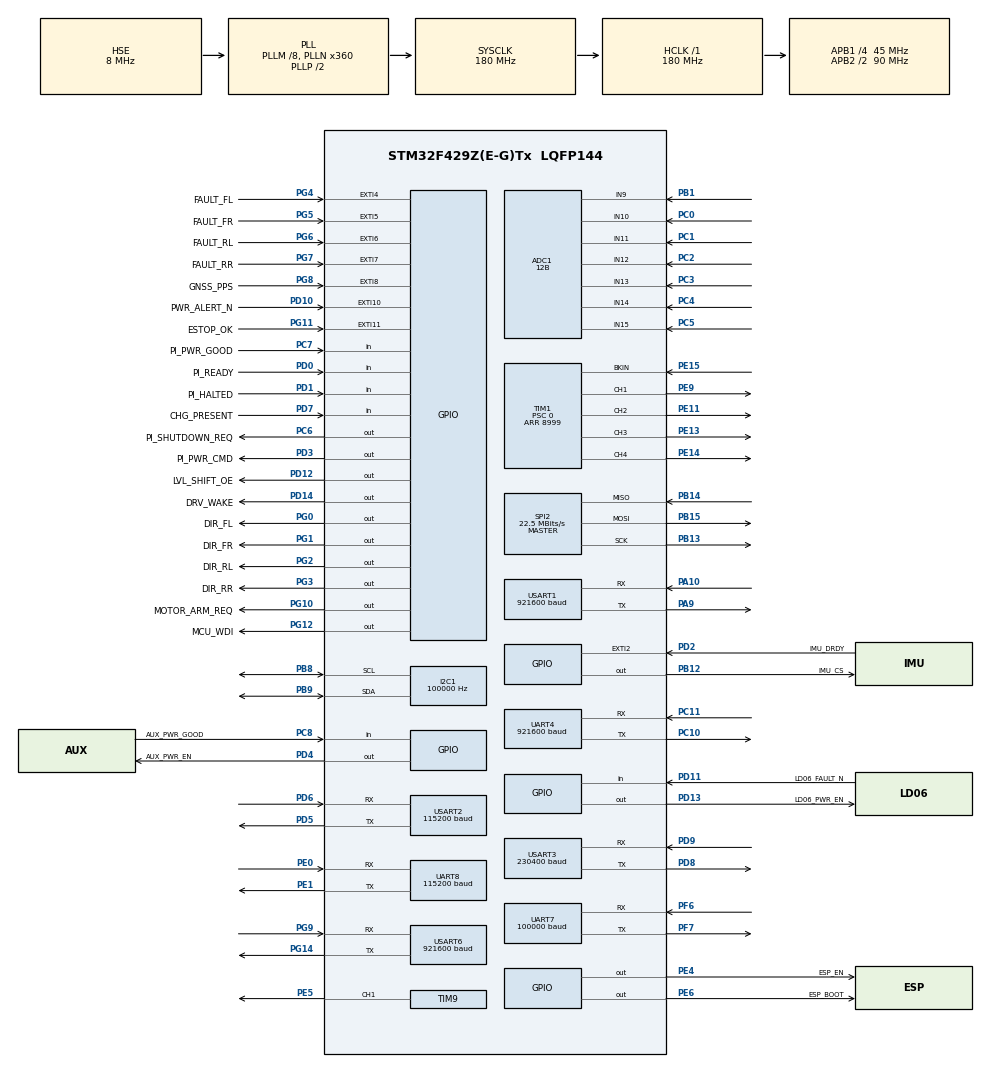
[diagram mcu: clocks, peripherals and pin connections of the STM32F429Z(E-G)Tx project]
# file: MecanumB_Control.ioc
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ADC1.Channel-0\#ChannelRegularConversion=ADC_CHANNEL_10
ADC1.Channel-1\#ChannelRegularConversion=ADC_CHANNEL_11
ADC1.Channel-2\#ChannelRegularConversion=ADC_CHANNEL_12
ADC1.Channel-3\#ChannelRegularConversion=ADC_CHANNEL_13
ADC1.Channel-4\#ChannelRegularConversion=ADC_CHANNEL_14
ADC1.Channel-5\#ChannelRegularConversion=ADC_CHANNEL_15
ADC1.Channel-6\#ChannelRegularConversion=ADC_CHANNEL_9
ADC1.ClockPrescaler=ADC_CLOCK_SYNC_PCLK_DIV4
ADC1.ContinuousConvMode=DISABLE
ADC1.DMAContinuousRequests=ENABLE
ADC1.EOCSelection=ADC_EOC_SINGLE_CONV
ADC1.ExternalTrigConv=ADC_EXTERNALTRIGCONV_T8_TRGO
ADC1.ExternalTrigConvEdge=ADC_EXTERNALTRIGCONVEDGE_RISING
ADC1.NbrOfConversion=7
ADC1.NbrOfConversionFlag=1
ADC1.Rank-0\#ChannelRegularConversion=1
ADC1.Rank-1\#ChannelRegularConversion=2
ADC1.Rank-2\#ChannelRegularConversion=3
ADC1.Rank-3\#ChannelRegularConversion=4
ADC1.Rank-4\#ChannelRegularConversion=5
ADC1.Rank-5\#ChannelRegularConversion=6
ADC1.Rank-6\#ChannelRegularConversion=7
ADC1.Resolution=ADC_RESOLUTION_12B
ADC1.SamplingTime-0\#ChannelRegularConversion=ADC_SAMPLETIME_56CYCLES
ADC1.SamplingTime-1\#ChannelRegularConversion=ADC_SAMPLETIME_56CYCLES
ADC1.SamplingTime-2\#ChannelRegularConversion=ADC_SAMPLETIME_56CYCLES
ADC1.SamplingTime-3\#ChannelRegularConversion=ADC_SAMPLETIME_56CYCLES
ADC1.SamplingTime-4\#ChannelRegularConversion=ADC_SAMPLETIME_56CYCLES
ADC1.SamplingTime-5\#ChannelRegularConversion=ADC_SAMPLETIME_56CYCLES
ADC1.SamplingTime-6\#ChannelRegularConversion=ADC_SAMPLETIME_144CYCLES
ADC1.ScanConvMode=ENABLE
ADC1.master=1
Dma.ADC1.0.Direction=DMA_PERIPH_TO_MEMORY
Dma.ADC1.0.FIFOMode=DMA_FIFOMODE_DISABLE
Dma.ADC1.0.Instance=DMA2_Stream0
Dma.ADC1.0.MemDataAlignment=DMA_MDATAALIGN_HALFWORD
Dma.ADC1.0.MemInc=DMA_MINC_ENABLE
Dma.ADC1.0.Mode=DMA_CIRCULAR
Dma.ADC1.0.PeriphDataAlignment=DMA_PDATAALIGN_HALFWORD
Dma.ADC1.0.PeriphInc=DMA_PINC_DISABLE
Dma.ADC1.0.Priority=DMA_PRIORITY_HIGH
Dma.Request0=ADC1
Dma.Request1=UART7_RX
Dma.Request2=USART2_RX
Dma.Request3=USART3_RX
Dma.Request4=UART4_RX
Dma.Request5=USART6_RX
Dma.Request6=USART6_TX
Dma.Request7=USART1_RX
Dma.Request8=USART1_TX
Dma.UART4_RX.4.Direction=DMA_PERIPH_TO_MEMORY
Dma.UART4_RX.4.FIFOMode=DMA_FIFOMODE_DISABLE
Dma.UART4_RX.4.Instance=DMA1_Stream2
Dma.UART4_RX.4.MemDataAlignment=DMA_MDATAALIGN_BYTE
Dma.UART4_RX.4.MemInc=DMA_MINC_ENABLE
Dma.UART4_RX.4.Mode=DMA_CIRCULAR
Dma.UART4_RX.4.PeriphDataAlignment=DMA_PDATAALIGN_BYTE
Dma.UART4_RX.4.PeriphInc=DMA_PINC_DISABLE
Dma.UART4_RX.4.Priority=DMA_PRIORITY_HIGH
Dma.UART7_RX.1.Direction=DMA_PERIPH_TO_MEMORY
Dma.UART7_RX.1.FIFOMode=DMA_FIFOMODE_DISABLE
Dma.UART7_RX.1.Instance=DMA1_Stream3
Dma.UART7_RX.1.MemDataAlignment=DMA_MDATAALIGN_BYTE
Dma.UART7_RX.1.MemInc=DMA_MINC_ENABLE
Dma.UART7_RX.1.Mode=DMA_CIRCULAR
Dma.UART7_RX.1.PeriphDataAlignment=DMA_PDATAALIGN_BYTE
Dma.UART7_RX.1.PeriphInc=DMA_PINC_DISABLE
Dma.UART7_RX.1.Priority=DMA_PRIORITY_VERY_HIGH
Dma.USART1_RX.7.Direction=DMA_PERIPH_TO_MEMORY
Dma.USART1_RX.7.FIFOMode=DMA_FIFOMODE_DISABLE
Dma.USART1_RX.7.Instance=DMA2_Stream2
Dma.USART1_RX.7.MemDataAlignment=DMA_MDATAALIGN_BYTE
Dma.USART1_RX.7.MemInc=DMA_MINC_ENABLE
Dma.USART1_RX.7.Mode=DMA_CIRCULAR
Dma.USART1_RX.7.PeriphDataAlignment=DMA_PDATAALIGN_BYTE
Dma.USART1_RX.7.PeriphInc=DMA_PINC_DISABLE
Dma.USART1_RX.7.Priority=DMA_PRIORITY_HIGH
Dma.USART1_TX.8.Direction=DMA_MEMORY_TO_PERIPH
Dma.USART1_TX.8.FIFOMode=DMA_FIFOMODE_DISABLE
Dma.USART1_TX.8.Instance=DMA2_Stream7
Dma.USART1_TX.8.MemDataAlignment=DMA_MDATAALIGN_BYTE
Dma.USART1_TX.8.MemInc=DMA_MINC_ENABLE
Dma.USART1_TX.8.Mode=DMA_NORMAL
Dma.USART1_TX.8.PeriphDataAlignment=DMA_PDATAALIGN_BYTE
Dma.USART1_TX.8.PeriphInc=DMA_PINC_DISABLE
Dma.USART1_TX.8.Priority=DMA_PRIORITY_MEDIUM
Dma.USART2_RX.2.Direction=DMA_PERIPH_TO_MEMORY
Dma.USART2_RX.2.FIFOMode=DMA_FIFOMODE_DISABLE
Dma.USART2_RX.2.Instance=DMA1_Stream5
Dma.USART2_RX.2.MemDataAlignment=DMA_MDATAALIGN_BYTE
Dma.USART2_RX.2.MemInc=DMA_MINC_ENABLE
Dma.USART2_RX.2.Mode=DMA_CIRCULAR
Dma.USART2_RX.2.PeriphDataAlignment=DMA_PDATAALIGN_BYTE
Dma.USART2_RX.2.PeriphInc=DMA_PINC_DISABLE
Dma.USART2_RX.2.Priority=DMA_PRIORITY_HIGH
Dma.USART3_RX.3.Direction=DMA_PERIPH_TO_MEMORY
Dma.USART3_RX.3.FIFOMode=DMA_FIFOMODE_DISABLE
Dma.USART3_RX.3.Instance=DMA1_Stream1
Dma.USART3_RX.3.MemDataAlignment=DMA_MDATAALIGN_BYTE
Dma.USART3_RX.3.MemInc=DMA_MINC_ENABLE
Dma.USART3_RX.3.Mode=DMA_CIRCULAR
Dma.USART3_RX.3.PeriphDataAlignment=DMA_PDATAALIGN_BYTE
Dma.USART3_RX.3.PeriphInc=DMA_PINC_DISABLE
Dma.USART3_RX.3.Priority=DMA_PRIORITY_HIGH
Dma.USART6_RX.5.Direction=DMA_PERIPH_TO_MEMORY
Dma.USART6_RX.5.FIFOMode=DMA_FIFOMODE_DISABLE
Dma.USART6_RX.5.Instance=DMA2_Stream1
Dma.USART6_RX.5.MemDataAlignment=DMA_MDATAALIGN_BYTE
Dma.USART6_RX.5.MemInc=DMA_MINC_ENABLE
Dma.USART6_RX.5.Mode=DMA_CIRCULAR
Dma.USART6_RX.5.PeriphDataAlignment=DMA_PDATAALIGN_BYTE
Dma.USART6_RX.5.PeriphInc=DMA_PINC_DISABLE
Dma.USART6_RX.5.Priority=DMA_PRIORITY_HIGH
Dma.USART6_TX.6.Direction=DMA_MEMORY_TO_PERIPH
Dma.USART6_TX.6.FIFOMode=DMA_FIFOMODE_DISABLE
Dma.USART6_TX.6.Instance=DMA2_Stream6
Dma.USART6_TX.6.MemDataAlignment=DMA_MDATAALIGN_BYTE
Dma.USART6_TX.6.MemInc=DMA_MINC_ENABLE
Dma.USART6_TX.6.Mode=DMA_NORMAL
Dma.USART6_TX.6.PeriphDataAlignment=DMA_PDATAALIGN_BYTE
Dma.USART6_TX.6.PeriphInc=DMA_PINC_DISABLE
Dma.USART6_TX.6.Priority=DMA_PRIORITY_MEDIUM
FREERTOS.Tasks01=defaultTask,0,128,StartDefaultTask,Default,NULL,Dynamic,NULL,NULL
FREERTOS.configCHECK_FOR_STACK_OVERFLOW=2
FREERTOS.configLIBRARY_MAX_SYSCALL_INTERRUPT_PRIORITY=5
FREERTOS.configMAX_PRIORITIES=16
FREERTOS.configMINIMAL_STACK_SIZE=128
FREERTOS.configTICK_RATE_HZ=1000
FREERTOS.configTOTAL_HEAP_SIZE=32768
FREERTOS.configUSE_16_BIT_TICKS=0
FREERTOS.configUSE_COUNTING_SEMAPHORES=1
FREERTOS.configUSE_IDLE_HOOK=0
FREERTOS.configUSE_MALLOC_FAILED_HOOK=1
FREERTOS.configUSE_MUTEXES=1
FREERTOS.configUSE_PORT_OPTIMISED_TASK_SELECTION=1
FREERTOS.configUSE_PREEMPTION=1
FREERTOS.configUSE_STATS_FORMATTING_FUNCTIONS=1
FREERTOS.configUSE_TICK_HOOK=0
FREERTOS.configUSE_TIMERS=0
FREERTOS.configUSE_TRACE_FACILITY=1
I2C1.ClockSpeed=100000
IWDG.Prescaler=IWDG_PRESCALER_32
IWDG.Reload=500
Mcu.Family=STM32F4
Mcu.Name=STM32F429Z(E-G)Tx
Mcu.Package=LQFP144
NVIC.DMA1_Stream1_IRQn=true\:6\:0\:true\:false\:true\:true\:true\:true\:true
NVIC.DMA1_Stream2_IRQn=true\:6\:0\:true\:false\:true\:true\:true\:true\:true
NVIC.DMA1_Stream3_IRQn=true\:6\:0\:true\:false\:true\:true\:true\:true\:true
NVIC.DMA1_Stream5_IRQn=true\:6\:0\:true\:false\:true\:true\:true\:true\:true
NVIC.DMA2_Stream0_IRQn=true\:6\:0\:true\:false\:true\:true\:true\:true\:true
NVIC.DMA2_Stream1_IRQn=true\:6\:0\:true\:false\:true\:true\:true\:true\:true
NVIC.DMA2_Stream2_IRQn=true\:6\:0\:true\:false\:true\:true\:true\:true\:true
NVIC.DMA2_Stream6_IRQn=true\:6\:0\:true\:false\:true\:true\:true\:true\:true
NVIC.DMA2_Stream7_IRQn=true\:6\:0\:true\:false\:true\:true\:true\:true\:true
NVIC.EXTI15_10_IRQn=true\:5\:0\:false\:false\:true\:true\:true\:true\:true
NVIC.EXTI2_IRQn=true\:6\:0\:true\:false\:true\:true\:true\:true\:true
NVIC.EXTI4_IRQn=true\:5\:0\:false\:false\:true\:true\:true\:true\:true
NVIC.EXTI9_5_IRQn=true\:5\:0\:false\:false\:true\:true\:true\:true\:true
NVIC.PriorityGroup=NVIC_PRIORITYGROUP_4
NVIC.TIM1_BRK_TIM9_IRQn=true\:5\:0\:false\:false\:true\:true\:true\:true\:true
NVIC.TIM6_DAC_IRQn=true\:5\:0\:true\:false\:true\:true\:true\:true\:true
NVIC.TIM7_IRQn=true\:14\:0\:false\:false\:true\:false\:false\:true\:true
NVIC.TimeBase=TIM7_IRQn
NVIC.TimeBaseIP=TIM7
NVIC.UART4_IRQn=true\:7\:0\:true\:false\:true\:true\:true\:true\:true
NVIC.UART7_IRQn=true\:7\:0\:true\:false\:true\:true\:true\:true\:true
NVIC.USART1_IRQn=true\:7\:0\:true\:false\:true\:true\:true\:true\:true
NVIC.USART2_IRQn=true\:7\:0\:true\:false\:true\:true\:true\:true\:true
NVIC.USART3_IRQn=true\:7\:0\:true\:false\:true\:true\:true\:true\:true
NVIC.USART6_IRQn=true\:7\:0\:true\:false\:true\:true\:true\:true\:true
PA0/WKUP.Signal=S_TIM5_CH1
PA1.Signal=S_TIM5_CH2
PA10.Mode=Asynchronous
PA10.Signal=USART1_RX
PA13.Mode=Serial_Wire
PA13.Signal=SYS_JTMS-SWDIO
PA14.Mode=Serial_Wire
PA14.Signal=SYS_JTCK-SWCLK
PA15.Signal=S_TIM2_CH1_ETR
PA6.Signal=S_TIM3_CH1
PA7.Signal=S_TIM3_CH2
PA9.Mode=Asynchronous
PA9.Signal=USART1_TX
PB1.Signal=ADCx_IN9
PB12.GPIO_Label=IMU_CS
PB12.GPIO_PuPd=GPIO_PULLUP
PB12.PinState=GPIO_PIN_SET
PB12.Signal=GPIO_Output
PB13.Mode=Full_Duplex_Master
PB13.Signal=SPI2_SCK
PB14.Mode=Full_Duplex_Master
PB14.Signal=SPI2_MISO
PB15.Mode=Full_Duplex_Master
PB15.Signal=SPI2_MOSI
PB3.Signal=S_TIM2_CH2
PB6.Signal=S_TIM4_CH1
PB7.Signal=S_TIM4_CH2
PB8.Mode=I2C
PB8.Signal=I2C1_SCL
PB9.Mode=I2C
PB9.Signal=I2C1_SDA
PC0.Signal=ADCx_IN10
PC1.Signal=ADCx_IN11
PC10.Mode=Asynchronous
PC10.Signal=UART4_TX
PC11.Mode=Asynchronous
PC11.Signal=UART4_RX
PC2.Signal=ADCx_IN12
PC3.Signal=ADCx_IN13
PC4.Signal=ADCx_IN14
PC5.Signal=ADCx_IN15
PC6.GPIO_Label=PI_SHUTDOWN_REQ
PC6.PinState=GPIO_PIN_RESET
PC6.Signal=GPIO_Output
PC7.GPIO_Label=PI_PWR_GOOD
PC7.GPIO_PuPd=GPIO_NOPULL
PC7.Signal=GPIO_Input
PC8.GPIO_Label=AUX_PWR_GOOD
PC8.GPIO_PuPd=GPIO_NOPULL
PC8.Signal=GPIO_Input
PD0.GPIO_Label=PI_READY
PD0.GPIO_PuPd=GPIO_PULLDOWN
PD0.Signal=GPIO_Input
PD1.GPIO_Label=PI_HALTED
PD1.GPIO_PuPd=GPIO_PULLDOWN
PD1.Signal=GPIO_Input
PD10.GPIO_Label=PWR_ALERT_N
PD10.GPIO_ModeDefaultEXTI=GPIO_MODE_IT_FALLING
PD10.GPIO_PuPd=GPIO_PULLUP
PD10.Signal=GPXTI10
PD11.GPIO_Label=LD06_FAULT_N
PD11.GPIO_PuPd=GPIO_PULLUP
PD11.Signal=GPIO_Input
PD12.GPIO_Label=LVL_SHIFT_OE
PD12.GPIO_PuPd=GPIO_PULLDOWN
PD12.Signal=GPIO_Output
PD13.GPIO_Label=LD06_PWR_EN
PD13.PinState=GPIO_PIN_RESET
PD13.GPIO_PuPd=GPIO_NOPULL
PD13.Signal=GPIO_Output
PD14.GPIO_Label=DRV_WAKE
PD14.PinState=GPIO_PIN_RESET
PD14.Signal=GPIO_Output
PD2.GPIO_Label=IMU_DRDY
PD2.GPIO_ModeDefaultEXTI=GPIO_MODE_IT_RISING
PD2.GPIO_PuPd=GPIO_PULLDOWN
PD2.Signal=GPXTI2
PD3.GPIO_Label=PI_PWR_CMD
PD3.PinState=GPIO_PIN_RESET
PD3.Signal=GPIO_Output
PD4.GPIO_Label=AUX_PWR_EN
PD4.PinState=GPIO_PIN_RESET
PD4.Signal=GPIO_Output
PD5.Mode=Asynchronous
PD5.Signal=USART2_TX
PD6.Mode=Asynchronous
PD6.Signal=USART2_RX
PD7.GPIO_Label=CHG_PRESENT
PD7.GPIO_PuPd=GPIO_NOPULL
PD7.Signal=GPIO_Input
PD8.Mode=Asynchronous
PD8.Signal=USART3_TX
PD9.Mode=Asynchronous
PD9.Signal=USART3_RX
PE0.Mode=Asynchronous
PE0.Signal=UART8_RX
PE1.Mode=Asynchronous
PE1.Signal=UART8_TX
PE11.Signal=S_TIM1_CH2
PE13.Signal=S_TIM1_CH3
PE14.Signal=S_TIM1_CH4
PE15.Mode=Activate-Break-Input
PE15.Signal=TIM1_BKIN
PE5.Signal=S_TIM9_CH1
PE9.Signal=S_TIM1_CH1
PF6.Mode=Asynchronous
PF6.Signal=UART7_RX
PF7.Mode=Asynchronous
PF7.Signal=UART7_TX
PG0.GPIO_Label=DIR_FL
PG0.PinState=GPIO_PIN_RESET
PG0.Signal=GPIO_Output
PG1.GPIO_Label=DIR_FR
PG1.PinState=GPIO_PIN_RESET
PG1.Signal=GPIO_Output
PG10.GPIO_Label=MOTOR_ARM_REQ
PG10.GPIO_PuPd=GPIO_PULLDOWN
PG10.Signal=GPIO_Output
PG11.GPIO_Label=ESTOP_OK
PG11.GPIO_ModeDefaultEXTI=GPIO_MODE_IT_FALLING
PG11.GPIO_PuPd=GPIO_PULLUP
PG11.Signal=GPXTI11
PG12.GPIO_Label=MCU_WDI
PG12.PinState=GPIO_PIN_RESET
PG12.Signal=GPIO_Output
PG14.Mode=Asynchronous
PG14.Signal=USART6_TX
PG2.GPIO_Label=DIR_RL
PG2.PinState=GPIO_PIN_RESET
PG2.Signal=GPIO_Output
PG3.GPIO_Label=DIR_RR
PG3.PinState=GPIO_PIN_RESET
PG3.Signal=GPIO_Output
PG4.GPIO_Label=FAULT_FL
PG4.GPIO_ModeDefaultEXTI=GPIO_MODE_IT_FALLING
PG4.GPIO_PuPd=GPIO_PULLUP
PG4.Signal=GPXTI4
PG5.GPIO_Label=FAULT_FR
PG5.GPIO_ModeDefaultEXTI=GPIO_MODE_IT_FALLING
PG5.GPIO_PuPd=GPIO_PULLUP
PG5.Signal=GPXTI5
PG6.GPIO_Label=FAULT_RL
PG6.GPIO_ModeDefaultEXTI=GPIO_MODE_IT_FALLING
PG6.GPIO_PuPd=GPIO_PULLUP
PG6.Signal=GPXTI6
PG7.GPIO_Label=FAULT_RR
PG7.GPIO_ModeDefaultEXTI=GPIO_MODE_IT_FALLING
PG7.GPIO_PuPd=GPIO_PULLUP
PG7.Signal=GPXTI7
PG8.GPIO_Label=GNSS_PPS
PG8.GPIO_ModeDefaultEXTI=GPIO_MODE_IT_RISING
PG8.GPIO_PuPd=GPIO_PULLDOWN
PG8.Signal=GPXTI8
PG9.Mode=Asynchronous
PG9.Signal=USART6_RX
PH0/OSC_IN.Mode=HSE-External-Oscillator
PH0/OSC_IN.Signal=RCC_OSC_IN
PH1/OSC_OUT.Mode=HSE-External-Oscillator
PH1/OSC_OUT.Signal=RCC_OSC_OUT
ProjectManager.HeapSize=0x200
ProjectManager.StackSize=0x400
ProjectManager.TargetToolchain=STM32CubeIDE
RCC.48MHZClocksFreq_Value=45000000
RCC.AHBCLKDivider=RCC_SYSCLK_DIV1
RCC.AHBFreq_Value=180000000
RCC.APB1CLKDivider=RCC_HCLK_DIV4
RCC.APB1Freq_Value=45000000
RCC.APB1TimFreq_Value=90000000
RCC.APB2CLKDivider=RCC_HCLK_DIV2
RCC.APB2Freq_Value=90000000
RCC.APB2TimFreq_Value=180000000
RCC.CortexFreq_Value=180000000
RCC.HCLKFreq_Value=180000000
RCC.HSE_VALUE=8000000
RCC.HSI_VALUE=16000000
RCC.LSE_VALUE=32768
RCC.PLLM=8
RCC.PLLN=360
RCC.PLLQ=8
RCC.PLLSAIN=192
RCC.SYSCLKFreq_VALUE=180000000
RCC.SYSCLKSource=RCC_SYSCLKSOURCE_PLLCLK
RCC.VCOOutputFreq_Value=360000000
SH.ADCx_IN10.0=ADC1_IN10,IN10
SH.ADCx_IN11.0=ADC1_IN11,IN11
SH.ADCx_IN12.0=ADC1_IN12,IN12
SH.ADCx_IN13.0=ADC1_IN13,IN13
SH.ADCx_IN14.0=ADC1_IN14,IN14
SH.ADCx_IN15.0=ADC1_IN15,IN15
SH.ADCx_IN9.0=ADC1_IN9,IN9
SH.S_TIM1_CH1.0=TIM1_CH1,PWM Generation1 CH1
SH.S_TIM1_CH2.0=TIM1_CH2,PWM Generation2 CH2
SH.S_TIM1_CH3.0=TIM1_CH3,PWM Generation3 CH3
SH.S_TIM1_CH4.0=TIM1_CH4,PWM Generation4 CH4
SH.S_TIM2_CH1_ETR.0=TIM2_CH1
SH.S_TIM2_CH2.0=TIM2_CH2
SH.S_TIM3_CH1.0=TIM3_CH1
SH.S_TIM3_CH2.0=TIM3_CH2
SH.S_TIM4_CH1.0=TIM4_CH1
SH.S_TIM4_CH2.0=TIM4_CH2
SH.S_TIM5_CH1.0=TIM5_CH1
SH.S_TIM5_CH2.0=TIM5_CH2
SH.S_TIM9_CH1.0=TIM9_CH1,PWM Generation1 CH1
SPI2.BaudRatePrescaler=SPI_BAUDRATEPRESCALER_4
SPI2.CLKPhase=SPI_PHASE_1EDGE
SPI2.CLKPolarity=SPI_POLARITY_LOW
SPI2.CalculateBaudRate=22.5 MBits/s
SPI2.DataSize=SPI_DATASIZE_8BIT
SPI2.Direction=SPI_DIRECTION_2LINES
SPI2.FirstBit=SPI_FIRSTBIT_MSB
SPI2.Mode=SPI_MODE_MASTER
SPI2.NSS=SPI_NSS_SOFT
SPI2.VirtualType=VM_MASTER
TIM1.AutomaticOutput=TIM_AUTOMATICOUTPUT_DISABLE
TIM1.BreakPolarity=TIM_BREAKPOLARITY_HIGH
TIM1.BreakState=TIM_BREAK_ENABLE
TIM1.Channel-PWM\ Generation1\ CH1=TIM_CHANNEL_1
TIM1.Channel-PWM\ Generation2\ CH2=TIM_CHANNEL_2
TIM1.Channel-PWM\ Generation3\ CH3=TIM_CHANNEL_3
TIM1.Channel-PWM\ Generation4\ CH4=TIM_CHANNEL_4
TIM1.CounterMode=TIM_COUNTERMODE_UP
TIM1.Period=8999
TIM1.Prescaler=0
TIM2.CombinedChannels=Encoder Mode
TIM2.EncoderMode=TIM_ENCODERMODE_TI12
TIM2.IC1Filter=0
TIM2.IC1Polarity=TIM_ICPOLARITY_RISING
TIM2.IC1Prescaler=TIM_ICPSC_DIV1
TIM2.IC1Selection=TIM_ICSELECTION_DIRECTTI
TIM2.IC2Filter=0
TIM2.IC2Polarity=TIM_ICPOLARITY_RISING
TIM2.IC2Prescaler=TIM_ICPSC_DIV1
TIM2.IC2Selection=TIM_ICSELECTION_DIRECTTI
TIM2.Period=4294967295
TIM2.Prescaler=0
TIM3.CombinedChannels=Encoder Mode
TIM3.EncoderMode=TIM_ENCODERMODE_TI12
TIM3.IC1Filter=0
TIM3.IC1Polarity=TIM_ICPOLARITY_RISING
TIM3.IC1Prescaler=TIM_ICPSC_DIV1
TIM3.IC1Selection=TIM_ICSELECTION_DIRECTTI
TIM3.IC2Filter=0
TIM3.IC2Polarity=TIM_ICPOLARITY_RISING
TIM3.IC2Prescaler=TIM_ICPSC_DIV1
TIM3.IC2Selection=TIM_ICSELECTION_DIRECTTI
TIM3.Period=65535
TIM3.Prescaler=0
TIM4.CombinedChannels=Encoder Mode
TIM4.EncoderMode=TIM_ENCODERMODE_TI12
TIM4.IC1Filter=0
TIM4.IC1Polarity=TIM_ICPOLARITY_RISING
TIM4.IC1Prescaler=TIM_ICPSC_DIV1
TIM4.IC1Selection=TIM_ICSELECTION_DIRECTTI
TIM4.IC2Filter=0
TIM4.IC2Polarity=TIM_ICPOLARITY_RISING
TIM4.IC2Prescaler=TIM_ICPSC_DIV1
TIM4.IC2Selection=TIM_ICSELECTION_DIRECTTI
TIM4.Period=65535
TIM4.Prescaler=0
TIM5.CombinedChannels=Encoder Mode
TIM5.EncoderMode=TIM_ENCODERMODE_TI12
TIM5.IC1Filter=0
TIM5.IC1Polarity=TIM_ICPOLARITY_RISING
TIM5.IC1Prescaler=TIM_ICPSC_DIV1
TIM5.IC1Selection=TIM_ICSELECTION_DIRECTTI
TIM5.IC2Filter=0
TIM5.IC2Polarity=TIM_ICPOLARITY_RISING
TIM5.IC2Prescaler=TIM_ICPSC_DIV1
TIM5.IC2Selection=TIM_ICSELECTION_DIRECTTI
TIM5.Period=4294967295
TIM5.Prescaler=0
TIM6.Period=999
TIM6.Prescaler=89
TIM8.Period=8999
TIM8.Prescaler=0
TIM8.TIM_MasterOutputTrigger=TIM_TRGO_UPDATE
TIM9.Channel-PWM\ Generation1\ CH1=TIM_CHANNEL_1
TIM9.Period=5999
TIM9.Prescaler=0
UART4.BaudRate=921600
UART4.VirtualMode=Asynchronous
UART7.BaudRate=100000
UART7.Parity=PARITY_EVEN
UART7.StopBits=UART_STOPBITS_2
UART7.VirtualMode=Asynchronous
UART7.WordLength=WORDLENGTH_9B
UART8.BaudRate=115200
UART8.VirtualMode=Asynchronous
USART1.BaudRate=921600
USART1.VirtualMode=VM_ASYNC
USART2.BaudRate=115200
USART2.VirtualMode=VM_ASYNC
USART3.BaudRate=230400
USART3.VirtualMode=VM_ASYNC
USART6.BaudRate=921600
USART6.VirtualMode=VM_ASYNC
VP_FREERTOS_VS_CMSIS_V1.Mode=CMSIS_V1
VP_IWDG_VS_IWDG.Mode=IWDG_Activate
VP_SYS_VS_tim7.Mode=TIM7
VP_TIM1_VS_ClockSourceINT.Mode=Internal
VP_TIM2_VS_ClockSourceINT.Mode=Internal
VP_TIM3_VS_ClockSourceINT.Mode=Internal
VP_TIM4_VS_ClockSourceINT.Mode=Internal
VP_TIM5_VS_ClockSourceINT.Mode=Internal
VP_TIM6_VS_ClockSourceINT.Mode=Enable_Timer
VP_TIM8_VS_ClockSourceINT.Mode=Internal
VP_TIM9_VS_ClockSourceINT.Mode=Internal
board=custom
RCC.PLLSourceVirtual=RCC_PLLSOURCE_HSE
PE4.GPIO_Label=ESP_EN
PE4.GPIO_ModeDefaultOutputPP=GPIO_MODE_OUTPUT_OD
PE4.PinState=GPIO_PIN_SET
PE4.Signal=GPIO_Output
PE6.GPIO_Label=ESP_BOOT
PE6.GPIO_ModeDefaultOutputPP=GPIO_MODE_OUTPUT_OD
PE6.PinState=GPIO_PIN_SET
PE6.Signal=GPIO_Output

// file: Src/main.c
/* USER CODE BEGIN Header */
/**
  ******************************************************************************
  * @file           : main.c
  * @brief          : Main program body
  ******************************************************************************
  * @attention
  *
  * Copyright (c) 2026 STMicroelectronics.
  * All rights reserved.
  *
  * This software is licensed under terms that can be found in the LICENSE file
  * in the root directory of this software component.
  * If no LICENSE file comes with this software, it is provided AS-IS.
  *
  ******************************************************************************
  */
/* USER CODE END Header */
#include "main.h"
#include "FreeRTOS.h"
#include "task.h"
#include "vehicle_app.h"

ADC_HandleTypeDef hadc1;
DMA_HandleTypeDef hdma_adc1;

I2C_HandleTypeDef hi2c1;

IWDG_HandleTypeDef hiwdg;

SPI_HandleTypeDef hspi2;

TIM_HandleTypeDef htim1;
TIM_HandleTypeDef htim2;
TIM_HandleTypeDef htim3;
TIM_HandleTypeDef htim4;
TIM_HandleTypeDef htim5;
TIM_HandleTypeDef htim6;
TIM_HandleTypeDef htim8;
TIM_HandleTypeDef htim9;

UART_HandleTypeDef huart4;
UART_HandleTypeDef huart7;
UART_HandleTypeDef huart8;
UART_HandleTypeDef huart1;
UART_HandleTypeDef huart2;
UART_HandleTypeDef huart3;
UART_HandleTypeDef huart6;
DMA_HandleTypeDef hdma_uart4_rx;
DMA_HandleTypeDef hdma_uart7_rx;
DMA_HandleTypeDef hdma_usart1_rx;
DMA_HandleTypeDef hdma_usart1_tx;
DMA_HandleTypeDef hdma_usart2_rx;
DMA_HandleTypeDef hdma_usart3_rx;
DMA_HandleTypeDef hdma_usart6_rx;
DMA_HandleTypeDef hdma_usart6_tx;

void SystemClock_Config(void);
static void MX_GPIO_Init(void);
static void MX_DMA_Init(void);
static void MX_ADC1_Init(void);
static void MX_I2C1_Init(void);
static void MX_IWDG_Init(void);
static void MX_SPI2_Init(void);
static void MX_TIM1_Init(void);
static void MX_TIM2_Init(void);
static void MX_TIM3_Init(void);
static void MX_TIM4_Init(void);
static void MX_TIM5_Init(void);
static void MX_TIM6_Init(void);
static void MX_TIM8_Init(void);
static void MX_TIM9_Init(void);
static void MX_UART4_Init(void);
static void MX_UART7_Init(void);
static void MX_UART8_Init(void);
static void MX_USART1_UART_Init(void);
static void MX_USART2_UART_Init(void);
static void MX_USART3_UART_Init(void);
static void MX_USART6_UART_Init(void);

int main(void)
{

  /* MCU Configuration--------------------------------------------------------*/

  /* Reset of all peripherals, Initializes the Flash interface and the Systick. */
  HAL_Init();

  /* Configure the system clock */
  SystemClock_Config();

  /* Initialize all configured peripherals */
  MX_GPIO_Init();
  MX_DMA_Init();
  MX_ADC1_Init();
  MX_I2C1_Init();
  MX_SPI2_Init();
  MX_TIM1_Init();
  MX_TIM2_Init();
  MX_TIM3_Init();
  MX_TIM4_Init();
  MX_TIM5_Init();
  MX_TIM6_Init();
  MX_TIM8_Init();
  MX_TIM9_Init();
  MX_UART4_Init();
  MX_UART7_Init();
  MX_UART8_Init();
  MX_USART1_UART_Init();
  MX_USART2_UART_Init();
  MX_USART3_UART_Init();
  MX_USART6_UART_Init();

  /* Create the thread(s) */
  /* definition and creation of defaultTask */
  vehicle_app_init();
  /* Start the independent watchdog only after parameter-store boot recovery:
   * a full 128 KiB sector erase can exceed the 500 ms timeout. */
  MX_IWDG_Init();

  /* Start scheduler */
  vTaskStartScheduler();
  Error_Handler();

  /* We should never get here as control is now taken by the scheduler */

  /* Infinite loop */
  while (1)
  {

  }
}

void SystemClock_Config(void)
{
  RCC_OscInitTypeDef RCC_OscInitStruct = {0};
  RCC_ClkInitTypeDef RCC_ClkInitStruct = {0};

  /** Configure the main internal regulator output voltage
  */
  __HAL_RCC_PWR_CLK_ENABLE();
  __HAL_PWR_VOLTAGESCALING_CONFIG(PWR_REGULATOR_VOLTAGE_SCALE1);

  /** Initializes the RCC Oscillators according to the specified parameters
  * in the RCC_OscInitTypeDef structure.
  */
  RCC_OscInitStruct.OscillatorType = RCC_OSCILLATORTYPE_HSE|RCC_OSCILLATORTYPE_LSI;
  RCC_OscInitStruct.HSEState = RCC_HSE_ON;
  RCC_OscInitStruct.HSIState = RCC_HSI_ON;
  RCC_OscInitStruct.HSICalibrationValue = RCC_HSICALIBRATION_DEFAULT;
  RCC_OscInitStruct.LSIState = RCC_LSI_ON;
  RCC_OscInitStruct.PLL.PLLState = RCC_PLL_ON;
  RCC_OscInitStruct.PLL.PLLSource = RCC_PLLSOURCE_HSE;
  RCC_OscInitStruct.PLL.PLLM = 8;
  RCC_OscInitStruct.PLL.PLLN = 360;
  RCC_OscInitStruct.PLL.PLLP = RCC_PLLP_DIV2;
  RCC_OscInitStruct.PLL.PLLQ = 8;
  if (HAL_RCC_OscConfig(&RCC_OscInitStruct) != HAL_OK)
  {
    Error_Handler();
  }

  /** Activate the Over-Drive mode
  */
  if (HAL_PWREx_EnableOverDrive() != HAL_OK)
  {
    Error_Handler();
  }

  /** Initializes the CPU, AHB and APB buses clocks
  */
  RCC_ClkInitStruct.ClockType = RCC_CLOCKTYPE_HCLK|RCC_CLOCKTYPE_SYSCLK
                              |RCC_CLOCKTYPE_PCLK1|RCC_CLOCKTYPE_PCLK2;
  RCC_ClkInitStruct.SYSCLKSource = RCC_SYSCLKSOURCE_PLLCLK;
  RCC_ClkInitStruct.AHBCLKDivider = RCC_SYSCLK_DIV1;
  RCC_ClkInitStruct.APB1CLKDivider = RCC_HCLK_DIV4;
  RCC_ClkInitStruct.APB2CLKDivider = RCC_HCLK_DIV2;

  if (HAL_RCC_ClockConfig(&RCC_ClkInitStruct, FLASH_LATENCY_5) != HAL_OK)
  {
    Error_Handler();
  }
}

static void MX_ADC1_Init(void)
{

  ADC_ChannelConfTypeDef sConfig = {0};

  /** Configure the global features of the ADC (Clock, Resolution, Data Alignment and number of conversion)
  */
  hadc1.Instance = ADC1;
  hadc1.Init.ClockPrescaler = ADC_CLOCK_SYNC_PCLK_DIV4;
  hadc1.Init.Resolution = ADC_RESOLUTION_12B;
  hadc1.Init.ScanConvMode = ENABLE;
  hadc1.Init.ContinuousConvMode = DISABLE;
  hadc1.Init.DiscontinuousConvMode = DISABLE;
  hadc1.Init.ExternalTrigConvEdge = ADC_EXTERNALTRIGCONVEDGE_RISING;
  hadc1.Init.ExternalTrigConv = ADC_EXTERNALTRIGCONV_T8_TRGO;
  hadc1.Init.DataAlign = ADC_DATAALIGN_RIGHT;
  hadc1.Init.NbrOfConversion = 7;
  hadc1.Init.DMAContinuousRequests = ENABLE;
  hadc1.Init.EOCSelection = ADC_EOC_SINGLE_CONV;
  if (HAL_ADC_Init(&hadc1) != HAL_OK)
  {
    Error_Handler();
  }

  /** Configure for the selected ADC regular channel its corresponding rank in the sequencer and its sample time.
  */
  sConfig.Channel = ADC_CHANNEL_10;
  sConfig.Rank = 1;
  sConfig.SamplingTime = ADC_SAMPLETIME_56CYCLES;
  if (HAL_ADC_ConfigChannel(&hadc1, &sConfig) != HAL_OK)
  {
    Error_Handler();
  }

  /** Configure for the selected ADC regular channel its corresponding rank in the sequencer and its sample time.
  */
  sConfig.Channel = ADC_CHANNEL_11;
  sConfig.Rank = 2;
  if (HAL_ADC_ConfigChannel(&hadc1, &sConfig) != HAL_OK)
  {
    Error_Handler();
  }

  /** Configure for the selected ADC regular channel its corresponding rank in the sequencer and its sample time.
  */
  sConfig.Channel = ADC_CHANNEL_12;
  sConfig.Rank = 3;
  if (HAL_ADC_ConfigChannel(&hadc1, &sConfig) != HAL_OK)
  {
    Error_Handler();
  }

  /** Configure for the selected ADC regular channel its corresponding rank in the sequencer and its sample time.
  */
  sConfig.Channel = ADC_CHANNEL_13;
  sConfig.Rank = 4;
  if (HAL_ADC_ConfigChannel(&hadc1, &sConfig) != HAL_OK)
  {
    Error_Handler();
  }

  /** Configure for the selected ADC regular channel its corresponding rank in the sequencer and its sample time.
  */
  sConfig.Channel = ADC_CHANNEL_14;
  sConfig.Rank = 5;
  if (HAL_ADC_ConfigChannel(&hadc1, &sConfig) != HAL_OK)
  {
    Error_Handler();
  }

  /** Configure for the selected ADC regular channel its corresponding rank in the sequencer and its sample time.
  */
  sConfig.Channel = ADC_CHANNEL_15;
  sConfig.Rank = 6;
  if (HAL_ADC_ConfigChannel(&hadc1, &sConfig) != HAL_OK)
  {
    Error_Handler();
  }

  /** Configure for the selected ADC regular channel its corresponding rank in the sequencer and its sample time.
  */
  sConfig.Channel = ADC_CHANNEL_9;
  sConfig.Rank = 7;
  sConfig.SamplingTime = ADC_SAMPLETIME_144CYCLES;
  if (HAL_ADC_ConfigChannel(&hadc1, &sConfig) != HAL_OK)
  {
    Error_Handler();
  }

}

static void MX_I2C1_Init(void)
{

  hi2c1.Instance = I2C1;
  hi2c1.Init.ClockSpeed = 100000;
  hi2c1.Init.DutyCycle = I2C_DUTYCYCLE_2;
  hi2c1.Init.OwnAddress1 = 0;
  hi2c1.Init.AddressingMode = I2C_ADDRESSINGMODE_7BIT;
  hi2c1.Init.DualAddressMode = I2C_DUALADDRESS_DISABLE;
  hi2c1.Init.OwnAddress2 = 0;
  hi2c1.Init.GeneralCallMode = I2C_GENERALCALL_DISABLE;
  hi2c1.Init.NoStretchMode = I2C_NOSTRETCH_DISABLE;
  if (HAL_I2C_Init(&hi2c1) != HAL_OK)
  {
    Error_Handler();
  }

  /** Configure Analogue filter
  */
  if (HAL_I2CEx_ConfigAnalogFilter(&hi2c1, I2C_ANALOGFILTER_ENABLE) != HAL_OK)
  {
    Error_Handler();
  }

  /** Configure Digital filter
  */
  if (HAL_I2CEx_ConfigDigitalFilter(&hi2c1, 0) != HAL_OK)
  {
    Error_Handler();
  }

}

static void MX_IWDG_Init(void)
{

  hiwdg.Instance = IWDG;
  hiwdg.Init.Prescaler = IWDG_PRESCALER_32;
  hiwdg.Init.Reload = 500;
  if (HAL_IWDG_Init(&hiwdg) != HAL_OK)
  {
    Error_Handler();
  }

}

static void MX_SPI2_Init(void)
{

  /* SPI2 parameter configuration*/
  hspi2.Instance = SPI2;
  hspi2.Init.Mode = SPI_MODE_MASTER;
  hspi2.Init.Direction = SPI_DIRECTION_2LINES;
  hspi2.Init.DataSize = SPI_DATASIZE_8BIT;
  hspi2.Init.CLKPolarity = SPI_POLARITY_LOW;
  hspi2.Init.CLKPhase = SPI_PHASE_1EDGE;
  hspi2.Init.NSS = SPI_NSS_SOFT;
  hspi2.Init.BaudRatePrescaler = SPI_BAUDRATEPRESCALER_4;
  hspi2.Init.FirstBit = SPI_FIRSTBIT_MSB;
  hspi2.Init.TIMode = SPI_TIMODE_DISABLE;
  hspi2.Init.CRCCalculation = SPI_CRCCALCULATION_DISABLE;
  hspi2.Init.CRCPolynomial = 10;
  if (HAL_SPI_Init(&hspi2) != HAL_OK)
  {
    Error_Handler();
  }

}

static void MX_TIM1_Init(void)
{

  TIM_ClockConfigTypeDef sClockSourceConfig = {0};
  TIM_MasterConfigTypeDef sMasterConfig = {0};
  TIM_OC_InitTypeDef sConfigOC = {0};
  TIM_BreakDeadTimeConfigTypeDef sBreakDeadTimeConfig = {0};

  htim1.Instance = TIM1;
  htim1.Init.Prescaler = 0;
  htim1.Init.CounterMode = TIM_COUNTERMODE_UP;
  htim1.Init.Period = 8999;
  htim1.Init.ClockDivision = TIM_CLOCKDIVISION_DIV1;
  htim1.Init.RepetitionCounter = 0;
  htim1.Init.AutoReloadPreload = TIM_AUTORELOAD_PRELOAD_DISABLE;
  if (HAL_TIM_Base_Init(&htim1) != HAL_OK)
  {
    Error_Handler();
  }
  sClockSourceConfig.ClockSource = TIM_CLOCKSOURCE_INTERNAL;
  if (HAL_TIM_ConfigClockSource(&htim1, &sClockSourceConfig) != HAL_OK)
  {
    Error_Handler();
  }
  if (HAL_TIM_PWM_Init(&htim1) != HAL_OK)
  {
    Error_Handler();
  }
  sMasterConfig.MasterOutputTrigger = TIM_TRGO_RESET;
  sMasterConfig.MasterSlaveMode = TIM_MASTERSLAVEMODE_DISABLE;
  if (HAL_TIMEx_MasterConfigSynchronization(&htim1, &sMasterConfig) != HAL_OK)
  {
    Error_Handler();
  }
  sConfigOC.OCMode = TIM_OCMODE_PWM1;
  sConfigOC.Pulse = 0;
  sConfigOC.OCPolarity = TIM_OCPOLARITY_HIGH;
  sConfigOC.OCNPolarity = TIM_OCNPOLARITY_HIGH;
  sConfigOC.OCFastMode = TIM_OCFAST_DISABLE;
  sConfigOC.OCIdleState = TIM_OCIDLESTATE_RESET;
  sConfigOC.OCNIdleState = TIM_OCNIDLESTATE_RESET;
  if (HAL_TIM_PWM_ConfigChannel(&htim1, &sConfigOC, TIM_CHANNEL_1) != HAL_OK)
  {
    Error_Handler();
  }
  if (HAL_TIM_PWM_ConfigChannel(&htim1, &sConfigOC, TIM_CHANNEL_2) != HAL_OK)
  {
    Error_Handler();
  }
  if (HAL_TIM_PWM_ConfigChannel(&htim1, &sConfigOC, TIM_CHANNEL_3) != HAL_OK)
  {
    Error_Handler();
  }
  if (HAL_TIM_PWM_ConfigChannel(&htim1, &sConfigOC, TIM_CHANNEL_4) != HAL_OK)
  {
    Error_Handler();
  }
  sBreakDeadTimeConfig.OffStateRunMode = TIM_OSSR_DISABLE;
  sBreakDeadTimeConfig.OffStateIDLEMode = TIM_OSSI_DISABLE;
  sBreakDeadTimeConfig.LockLevel = TIM_LOCKLEVEL_OFF;
  sBreakDeadTimeConfig.DeadTime = 0;
  sBreakDeadTimeConfig.BreakState = TIM_BREAK_ENABLE;
  sBreakDeadTimeConfig.BreakPolarity = TIM_BREAKPOLARITY_HIGH;
  sBreakDeadTimeConfig.AutomaticOutput = TIM_AUTOMATICOUTPUT_DISABLE;
  if (HAL_TIMEx_ConfigBreakDeadTime(&htim1, &sBreakDeadTimeConfig) != HAL_OK)
  {
    Error_Handler();
  }
  HAL_TIM_MspPostInit(&htim1);

}

static void MX_TIM2_Init(void)
{

  TIM_ClockConfigTypeDef sClockSourceConfig = {0};
  TIM_MasterConfigTypeDef sMasterConfig = {0};

  htim2.Instance = TIM2;
  htim2.Init.Prescaler = 0;
  htim2.Init.CounterMode = TIM_COUNTERMODE_UP;
  htim2.Init.Period = 4294967295;
  htim2.Init.ClockDivision = TIM_CLOCKDIVISION_DIV1;
  htim2.Init.AutoReloadPreload = TIM_AUTORELOAD_PRELOAD_DISABLE;
  if (HAL_TIM_Base_Init(&htim2) != HAL_OK)
  {
    Error_Handler();
  }
  sClockSourceConfig.ClockSource = TIM_CLOCKSOURCE_INTERNAL;
  if (HAL_TIM_ConfigClockSource(&htim2, &sClockSourceConfig) != HAL_OK)
  {
    Error_Handler();
  }
  sMasterConfig.MasterOutputTrigger = TIM_TRGO_RESET;
  sMasterConfig.MasterSlaveMode = TIM_MASTERSLAVEMODE_DISABLE;
  if (HAL_TIMEx_MasterConfigSynchronization(&htim2, &sMasterConfig) != HAL_OK)
  {
    Error_Handler();
  }

}

static void MX_TIM3_Init(void)
{

  TIM_ClockConfigTypeDef sClockSourceConfig = {0};
  TIM_MasterConfigTypeDef sMasterConfig = {0};

  htim3.Instance = TIM3;
  htim3.Init.Prescaler = 0;
  htim3.Init.CounterMode = TIM_COUNTERMODE_UP;
  htim3.Init.Period = 65535;
  htim3.Init.ClockDivision = TIM_CLOCKDIVISION_DIV1;
  htim3.Init.AutoReloadPreload = TIM_AUTORELOAD_PRELOAD_DISABLE;
  if (HAL_TIM_Base_Init(&htim3) != HAL_OK)
  {
    Error_Handler();
  }
  sClockSourceConfig.ClockSource = TIM_CLOCKSOURCE_INTERNAL;
  if (HAL_TIM_ConfigClockSource(&htim3, &sClockSourceConfig) != HAL_OK)
  {
    Error_Handler();
  }
  sMasterConfig.MasterOutputTrigger = TIM_TRGO_RESET;
  sMasterConfig.MasterSlaveMode = TIM_MASTERSLAVEMODE_DISABLE;
  if (HAL_TIMEx_MasterConfigSynchronization(&htim3, &sMasterConfig) != HAL_OK)
  {
    Error_Handler();
  }

}

static void MX_TIM4_Init(void)
{

  TIM_ClockConfigTypeDef sClockSourceConfig = {0};
  TIM_MasterConfigTypeDef sMasterConfig = {0};

  htim4.Instance = TIM4;
  htim4.Init.Prescaler = 0;
  htim4.Init.CounterMode = TIM_COUNTERMODE_UP;
  htim4.Init.Period = 65535;
  htim4.Init.ClockDivision = TIM_CLOCKDIVISION_DIV1;
  htim4.Init.AutoReloadPreload = TIM_AUTORELOAD_PRELOAD_DISABLE;
  if (HAL_TIM_Base_Init(&htim4) != HAL_OK)
  {
    Error_Handler();
  }
  sClockSourceConfig.ClockSource = TIM_CLOCKSOURCE_INTERNAL;
  if (HAL_TIM_ConfigClockSource(&htim4, &sClockSourceConfig) != HAL_OK)
  {
    Error_Handler();
  }
  sMasterConfig.MasterOutputTrigger = TIM_TRGO_RESET;
  sMasterConfig.MasterSlaveMode = TIM_MASTERSLAVEMODE_DISABLE;
  if (HAL_TIMEx_MasterConfigSynchronization(&htim4, &sMasterConfig) != HAL_OK)
  {
    Error_Handler();
  }

}

static void MX_TIM5_Init(void)
{

  TIM_ClockConfigTypeDef sClockSourceConfig = {0};
  TIM_MasterConfigTypeDef sMasterConfig = {0};

  htim5.Instance = TIM5;
  htim5.Init.Prescaler = 0;
  htim5.Init.CounterMode = TIM_COUNTERMODE_UP;
  htim5.Init.Period = 4294967295;
  htim5.Init.ClockDivision = TIM_CLOCKDIVISION_DIV1;
  htim5.Init.AutoReloadPreload = TIM_AUTORELOAD_PRELOAD_DISABLE;
  if (HAL_TIM_Base_Init(&htim5) != HAL_OK)
  {
    Error_Handler();
  }
  sClockSourceConfig.ClockSource = TIM_CLOCKSOURCE_INTERNAL;
  if (HAL_TIM_ConfigClockSource(&htim5, &sClockSourceConfig) != HAL_OK)
  {
    Error_Handler();
  }
  sMasterConfig.MasterOutputTrigger = TIM_TRGO_RESET;
  sMasterConfig.MasterSlaveMode = TIM_MASTERSLAVEMODE_DISABLE;
  if (HAL_TIMEx_MasterConfigSynchronization(&htim5, &sMasterConfig) != HAL_OK)
  {
    Error_Handler();
  }

}

static void MX_TIM6_Init(void)
{

  TIM_MasterConfigTypeDef sMasterConfig = {0};

  htim6.Instance = TIM6;
  htim6.Init.Prescaler = 89;
  htim6.Init.CounterMode = TIM_COUNTERMODE_UP;
  htim6.Init.Period = 999;
  htim6.Init.AutoReloadPreload = TIM_AUTORELOAD_PRELOAD_DISABLE;
  if (HAL_TIM_Base_Init(&htim6) != HAL_OK)
  {
    Error_Handler();
  }
  sMasterConfig.MasterOutputTrigger = TIM_TRGO_RESET;
  sMasterConfig.MasterSlaveMode = TIM_MASTERSLAVEMODE_DISABLE;
  if (HAL_TIMEx_MasterConfigSynchronization(&htim6, &sMasterConfig) != HAL_OK)
  {
    Error_Handler();
  }

}

static void MX_TIM8_Init(void)
{

  TIM_ClockConfigTypeDef sClockSourceConfig = {0};
  TIM_MasterConfigTypeDef sMasterConfig = {0};

  htim8.Instance = TIM8;
  htim8.Init.Prescaler = 0;
  htim8.Init.CounterMode = TIM_COUNTERMODE_UP;
  htim8.Init.Period = 8999;
  htim8.Init.ClockDivision = TIM_CLOCKDIVISION_DIV1;
  htim8.Init.RepetitionCounter = 0;
  htim8.Init.AutoReloadPreload = TIM_AUTORELOAD_PRELOAD_DISABLE;
  if (HAL_TIM_Base_Init(&htim8) != HAL_OK)
  {
    Error_Handler();
  }
  sClockSourceConfig.ClockSource = TIM_CLOCKSOURCE_INTERNAL;
  if (HAL_TIM_ConfigClockSource(&htim8, &sClockSourceConfig) != HAL_OK)
  {
    Error_Handler();
  }
  sMasterConfig.MasterOutputTrigger = TIM_TRGO_UPDATE;
  sMasterConfig.MasterSlaveMode = TIM_MASTERSLAVEMODE_DISABLE;
  if (HAL_TIMEx_MasterConfigSynchronization(&htim8, &sMasterConfig) != HAL_OK)
  {
    Error_Handler();
  }

}

static void MX_TIM9_Init(void)
{

  TIM_ClockConfigTypeDef sClockSourceConfig = {0};
  TIM_OC_InitTypeDef sConfigOC = {0};

  htim9.Instance = TIM9;
  htim9.Init.Prescaler = 0;
  htim9.Init.CounterMode = TIM_COUNTERMODE_UP;
  htim9.Init.Period = 5999;
  htim9.Init.ClockDivision = TIM_CLOCKDIVISION_DIV1;
  htim9.Init.AutoReloadPreload = TIM_AUTORELOAD_PRELOAD_DISABLE;
  if (HAL_TIM_Base_Init(&htim9) != HAL_OK)
  {
    Error_Handler();
  }
  sClockSourceConfig.ClockSource = TIM_CLOCKSOURCE_INTERNAL;
  if (HAL_TIM_ConfigClockSource(&htim9, &sClockSourceConfig) != HAL_OK)
  {
    Error_Handler();
  }
  if (HAL_TIM_PWM_Init(&htim9) != HAL_OK)
  {
    Error_Handler();
  }
  sConfigOC.OCMode = TIM_OCMODE_PWM1;
  sConfigOC.Pulse = 0;
  sConfigOC.OCPolarity = TIM_OCPOLARITY_HIGH;
  sConfigOC.OCFastMode = TIM_OCFAST_DISABLE;
  if (HAL_TIM_PWM_ConfigChannel(&htim9, &sConfigOC, TIM_CHANNEL_1) != HAL_OK)
  {
    Error_Handler();
  }
  HAL_TIM_MspPostInit(&htim9);

}

static void MX_UART4_Init(void)
{

  huart4.Instance = UART4;
  huart4.Init.BaudRate = 921600;
  huart4.Init.WordLength = UART_WORDLENGTH_8B;
  huart4.Init.StopBits = UART_STOPBITS_1;
  huart4.Init.Parity = UART_PARITY_NONE;
  huart4.Init.Mode = UART_MODE_TX_RX;
  huart4.Init.HwFlowCtl = UART_HWCONTROL_NONE;
  huart4.Init.OverSampling = UART_OVERSAMPLING_16;
  if (HAL_UART_Init(&huart4) != HAL_OK)
  {
    Error_Handler();
  }

}

static void MX_UART7_Init(void)
{

  huart7.Instance = UART7;
  huart7.Init.BaudRate = 100000;
  huart7.Init.WordLength = UART_WORDLENGTH_9B;
  huart7.Init.StopBits = UART_STOPBITS_2;
  huart7.Init.Parity = UART_PARITY_EVEN;
  huart7.Init.Mode = UART_MODE_TX_RX;
  huart7.Init.HwFlowCtl = UART_HWCONTROL_NONE;
  huart7.Init.OverSampling = UART_OVERSAMPLING_16;
  if (HAL_UART_Init(&huart7) != HAL_OK)
  {
    Error_Handler();
  }

}

static void MX_UART8_Init(void)
{

  huart8.Instance = UART8;
  huart8.Init.BaudRate = 115200;
  huart8.Init.WordLength = UART_WORDLENGTH_8B;
  huart8.Init.StopBits = UART_STOPBITS_1;
  huart8.Init.Parity = UART_PARITY_NONE;
  huart8.Init.Mode = UART_MODE_TX_RX;
  huart8.Init.HwFlowCtl = UART_HWCONTROL_NONE;
  huart8.Init.OverSampling = UART_OVERSAMPLING_16;
  if (HAL_UART_Init(&huart8) != HAL_OK)
  {
    Error_Handler();
  }

}

static void MX_USART1_UART_Init(void)
{

  huart1.Instance = USART1;
  huart1.Init.BaudRate = 921600;
  huart1.Init.WordLength = UART_WORDLENGTH_8B;
  huart1.Init.StopBits = UART_STOPBITS_1;
  huart1.Init.Parity = UART_PARITY_NONE;
  huart1.Init.Mode = UART_MODE_TX_RX;
  huart1.Init.HwFlowCtl = UART_HWCONTROL_NONE;
  huart1.Init.OverSampling = UART_OVERSAMPLING_16;
  if (HAL_UART_Init(&huart1) != HAL_OK)
  {
    Error_Handler();
  }

}

static void MX_USART2_UART_Init(void)
{

  huart2.Instance = USART2;
  huart2.Init.BaudRate = 115200;
  huart2.Init.WordLength = UART_WORDLENGTH_8B;
  huart2.Init.StopBits = UART_STOPBITS_1;
  huart2.Init.Parity = UART_PARITY_NONE;
  huart2.Init.Mode = UART_MODE_TX_RX;
  huart2.Init.HwFlowCtl = UART_HWCONTROL_NONE;
  huart2.Init.OverSampling = UART_OVERSAMPLING_16;
  if (HAL_UART_Init(&huart2) != HAL_OK)
  {
    Error_Handler();
  }

}

static void MX_USART3_UART_Init(void)
{

  huart3.Instance = USART3;
  huart3.Init.BaudRate = 230400;
  huart3.Init.WordLength = UART_WORDLENGTH_8B;
  huart3.Init.StopBits = UART_STOPBITS_1;
  huart3.Init.Parity = UART_PARITY_NONE;
  huart3.Init.Mode = UART_MODE_TX_RX;
  huart3.Init.HwFlowCtl = UART_HWCONTROL_NONE;
  huart3.Init.OverSampling = UART_OVERSAMPLING_16;
  if (HAL_UART_Init(&huart3) != HAL_OK)
  {
    Error_Handler();
  }

}

static void MX_USART6_UART_Init(void)
{

  huart6.Instance = USART6;
  huart6.Init.BaudRate = 921600;
  huart6.Init.WordLength = UART_WORDLENGTH_8B;
  huart6.Init.StopBits = UART_STOPBITS_1;
  huart6.Init.Parity = UART_PARITY_NONE;
  huart6.Init.Mode = UART_MODE_TX_RX;
  huart6.Init.HwFlowCtl = UART_HWCONTROL_NONE;
  huart6.Init.OverSampling = UART_OVERSAMPLING_16;
  if (HAL_UART_Init(&huart6) != HAL_OK)
  {
    Error_Handler();
  }

}

static void MX_DMA_Init(void)
{

  /* DMA controller clock enable */
  __HAL_RCC_DMA2_CLK_ENABLE();
  __HAL_RCC_DMA1_CLK_ENABLE();

  /* DMA interrupt init */
  /* DMA1_Stream1_IRQn interrupt configuration */
  HAL_NVIC_SetPriority(DMA1_Stream1_IRQn, 6, 0);
  HAL_NVIC_EnableIRQ(DMA1_Stream1_IRQn);
  /* DMA1_Stream2_IRQn interrupt configuration */
  HAL_NVIC_SetPriority(DMA1_Stream2_IRQn, 6, 0);
  HAL_NVIC_EnableIRQ(DMA1_Stream2_IRQn);
  /* DMA1_Stream3_IRQn interrupt configuration */
  HAL_NVIC_SetPriority(DMA1_Stream3_IRQn, 6, 0);
  HAL_NVIC_EnableIRQ(DMA1_Stream3_IRQn);
  /* DMA1_Stream5_IRQn interrupt configuration */
  HAL_NVIC_SetPriority(DMA1_Stream5_IRQn, 6, 0);
  HAL_NVIC_EnableIRQ(DMA1_Stream5_IRQn);
  /* DMA2_Stream0_IRQn interrupt configuration */
  HAL_NVIC_SetPriority(DMA2_Stream0_IRQn, 6, 0);
  HAL_NVIC_EnableIRQ(DMA2_Stream0_IRQn);
  /* DMA2_Stream1_IRQn interrupt configuration */
  HAL_NVIC_SetPriority(DMA2_Stream1_IRQn, 6, 0);
  HAL_NVIC_EnableIRQ(DMA2_Stream1_IRQn);
  /* DMA2_Stream2_IRQn interrupt configuration */
  HAL_NVIC_SetPriority(DMA2_Stream2_IRQn, 6, 0);
  HAL_NVIC_EnableIRQ(DMA2_Stream2_IRQn);
  /* DMA2_Stream6_IRQn interrupt configuration */
  HAL_NVIC_SetPriority(DMA2_Stream6_IRQn, 6, 0);
  HAL_NVIC_EnableIRQ(DMA2_Stream6_IRQn);
  /* DMA2_Stream7_IRQn interrupt configuration */
  HAL_NVIC_SetPriority(DMA2_Stream7_IRQn, 6, 0);
  HAL_NVIC_EnableIRQ(DMA2_Stream7_IRQn);

}

static void MX_GPIO_Init(void)
{
  GPIO_InitTypeDef GPIO_InitStruct = {0};

  /* GPIO Ports Clock Enable */
  __HAL_RCC_GPIOE_CLK_ENABLE();
  __HAL_RCC_GPIOF_CLK_ENABLE();
  __HAL_RCC_GPIOH_CLK_ENABLE();
  __HAL_RCC_GPIOC_CLK_ENABLE();
  __HAL_RCC_GPIOA_CLK_ENABLE();
  __HAL_RCC_GPIOB_CLK_ENABLE();
  __HAL_RCC_GPIOG_CLK_ENABLE();
  __HAL_RCC_GPIOD_CLK_ENABLE();

  /*Configure GPIO pin Output Level */
  HAL_GPIO_WritePin(GPIOG, DIR_FL_Pin|DIR_FR_Pin|DIR_RL_Pin|DIR_RR_Pin
                          |MOTOR_ARM_REQ_Pin|MCU_WDI_Pin, GPIO_PIN_RESET);

  /*Configure GPIO pin Output Level */
  HAL_GPIO_WritePin(IMU_CS_GPIO_Port, IMU_CS_Pin, GPIO_PIN_SET);

  /*Configure GPIO pin Output Level */
  HAL_GPIO_WritePin(GPIOD, LVL_SHIFT_OE_Pin|DRV_WAKE_Pin|PI_PWR_CMD_Pin|AUX_PWR_EN_Pin|LD06_PWR_EN_Pin, GPIO_PIN_RESET);

  /*Configure GPIO pin Output Level */
  HAL_GPIO_WritePin(PI_SHUTDOWN_REQ_GPIO_Port, PI_SHUTDOWN_REQ_Pin, GPIO_PIN_RESET);

  /*Configure GPIO pins : DIR_FL_Pin DIR_FR_Pin DIR_RL_Pin DIR_RR_Pin
                           MCU_WDI_Pin */
  GPIO_InitStruct.Pin = DIR_FL_Pin|DIR_FR_Pin|DIR_RL_Pin|DIR_RR_Pin
                          |MCU_WDI_Pin;
  GPIO_InitStruct.Mode = GPIO_MODE_OUTPUT_PP;
  GPIO_InitStruct.Pull = GPIO_NOPULL;
  GPIO_InitStruct.Speed = GPIO_SPEED_FREQ_LOW;
  HAL_GPIO_Init(GPIOG, &GPIO_InitStruct);

  /*Configure GPIO pin : IMU_CS_Pin */
  GPIO_InitStruct.Pin = IMU_CS_Pin;
  GPIO_InitStruct.Mode = GPIO_MODE_OUTPUT_PP;
  GPIO_InitStruct.Pull = GPIO_PULLUP;
  GPIO_InitStruct.Speed = GPIO_SPEED_FREQ_LOW;
  HAL_GPIO_Init(IMU_CS_GPIO_Port, &GPIO_InitStruct);

  /*Configure GPIO pin : PWR_ALERT_N_Pin */
  GPIO_InitStruct.Pin = PWR_ALERT_N_Pin;
  GPIO_InitStruct.Mode = GPIO_MODE_IT_FALLING;
  GPIO_InitStruct.Pull = GPIO_PULLUP;
  HAL_GPIO_Init(PWR_ALERT_N_GPIO_Port, &GPIO_InitStruct);

  /*Configure GPIO pin : LVL_SHIFT_OE_Pin */
  GPIO_InitStruct.Pin = LVL_SHIFT_OE_Pin;
  GPIO_InitStruct.Mode = GPIO_MODE_OUTPUT_PP;
  GPIO_InitStruct.Pull = GPIO_PULLDOWN;
  GPIO_InitStruct.Speed = GPIO_SPEED_FREQ_LOW;
  HAL_GPIO_Init(LVL_SHIFT_OE_GPIO_Port, &GPIO_InitStruct);

  /*Configure GPIO pins : DRV_WAKE_Pin PI_PWR_CMD_Pin AUX_PWR_EN_Pin */
  GPIO_InitStruct.Pin = DRV_WAKE_Pin|PI_PWR_CMD_Pin|AUX_PWR_EN_Pin|LD06_PWR_EN_Pin;
  GPIO_InitStruct.Mode = GPIO_MODE_OUTPUT_PP;
  GPIO_InitStruct.Pull = GPIO_NOPULL;
  GPIO_InitStruct.Speed = GPIO_SPEED_FREQ_LOW;
  HAL_GPIO_Init(GPIOD, &GPIO_InitStruct);

  /*Configure GPIO pins : FAULT_FL_Pin FAULT_FR_Pin FAULT_RL_Pin FAULT_RR_Pin
                           ESTOP_OK_Pin */
  GPIO_InitStruct.Pin = FAULT_FL_Pin|FAULT_FR_Pin|FAULT_RL_Pin|FAULT_RR_Pin
                          |ESTOP_OK_Pin;
  GPIO_InitStruct.Mode = GPIO_MODE_IT_FALLING;
  GPIO_InitStruct.Pull = GPIO_PULLUP;
  HAL_GPIO_Init(GPIOG, &GPIO_InitStruct);

  /*Configure GPIO pin : GNSS_PPS_Pin */
  GPIO_InitStruct.Pin = GNSS_PPS_Pin;
  GPIO_InitStruct.Mode = GPIO_MODE_IT_RISING;
  GPIO_InitStruct.Pull = GPIO_PULLDOWN;
  HAL_GPIO_Init(GNSS_PPS_GPIO_Port, &GPIO_InitStruct);

  /*Configure GPIO pin : PI_SHUTDOWN_REQ_Pin */
  GPIO_InitStruct.Pin = PI_SHUTDOWN_REQ_Pin;
  GPIO_InitStruct.Mode = GPIO_MODE_OUTPUT_PP;
  GPIO_InitStruct.Pull = GPIO_NOPULL;
  GPIO_InitStruct.Speed = GPIO_SPEED_FREQ_LOW;
  HAL_GPIO_Init(PI_SHUTDOWN_REQ_GPIO_Port, &GPIO_InitStruct);

  /*Configure GPIO pins : PI_PWR_GOOD_Pin AUX_PWR_GOOD_Pin */
  GPIO_InitStruct.Pin = PI_PWR_GOOD_Pin|AUX_PWR_GOOD_Pin;
  GPIO_InitStruct.Mode = GPIO_MODE_INPUT;
  GPIO_InitStruct.Pull = GPIO_NOPULL;
  HAL_GPIO_Init(GPIOC, &GPIO_InitStruct);

  /*Configure GPIO pins : PI_READY_Pin PI_HALTED_Pin */
  GPIO_InitStruct.Pin = PI_READY_Pin|PI_HALTED_Pin;
  GPIO_InitStruct.Mode = GPIO_MODE_INPUT;
  GPIO_InitStruct.Pull = GPIO_PULLDOWN;
  HAL_GPIO_Init(GPIOD, &GPIO_InitStruct);

  /*Configure GPIO pin : IMU_DRDY_Pin */
  GPIO_InitStruct.Pin = IMU_DRDY_Pin;
  GPIO_InitStruct.Mode = GPIO_MODE_IT_RISING;
  GPIO_InitStruct.Pull = GPIO_PULLDOWN;
  HAL_GPIO_Init(IMU_DRDY_GPIO_Port, &GPIO_InitStruct);

  /*Configure GPIO pin : CHG_PRESENT_Pin */
  GPIO_InitStruct.Pin = CHG_PRESENT_Pin;
  GPIO_InitStruct.Mode = GPIO_MODE_INPUT;
  GPIO_InitStruct.Pull = GPIO_NOPULL;
  HAL_GPIO_Init(CHG_PRESENT_GPIO_Port, &GPIO_InitStruct);

  /*Configure GPIO pin : MOTOR_ARM_REQ_Pin */
  GPIO_InitStruct.Pin = MOTOR_ARM_REQ_Pin;
  GPIO_InitStruct.Mode = GPIO_MODE_OUTPUT_PP;
  GPIO_InitStruct.Pull = GPIO_PULLDOWN;
  GPIO_InitStruct.Speed = GPIO_SPEED_FREQ_LOW;
  HAL_GPIO_Init(MOTOR_ARM_REQ_GPIO_Port, &GPIO_InitStruct);

  /* EXTI interrupt init*/
  HAL_NVIC_SetPriority(EXTI2_IRQn, 6, 0);
  HAL_NVIC_EnableIRQ(EXTI2_IRQn);

  HAL_NVIC_SetPriority(EXTI4_IRQn, 3, 0);
  HAL_NVIC_EnableIRQ(EXTI4_IRQn);

  HAL_NVIC_SetPriority(EXTI9_5_IRQn, 3, 0);
  HAL_NVIC_EnableIRQ(EXTI9_5_IRQn);

  HAL_NVIC_SetPriority(EXTI15_10_IRQn, 3, 0);
  HAL_NVIC_EnableIRQ(EXTI15_10_IRQn);

  /* LD06 branch fault is polled; EXTI11 remains assigned to PG11 ESTOP. */
  GPIO_InitStruct.Pin = LD06_FAULT_N_Pin;
  GPIO_InitStruct.Mode = GPIO_MODE_INPUT;
  GPIO_InitStruct.Pull = GPIO_PULLUP;
  HAL_GPIO_Init(LD06_FAULT_N_GPIO_Port, &GPIO_InitStruct);

  /* USER CODE BEGIN MX_GPIO_Init_2 */

  /* External pull-ups select normal ESP32 boot; open drain permits pogo control. */
  HAL_GPIO_WritePin(GPIOE, ESP_EN_Pin|ESP_BOOT_Pin, GPIO_PIN_SET);
  GPIO_InitStruct.Pin = ESP_EN_Pin|ESP_BOOT_Pin;
  GPIO_InitStruct.Mode = GPIO_MODE_OUTPUT_OD;
  GPIO_InitStruct.Pull = GPIO_NOPULL;
  GPIO_InitStruct.Speed = GPIO_SPEED_FREQ_LOW;
  HAL_GPIO_Init(GPIOE, &GPIO_InitStruct);

  /* USER CODE END MX_GPIO_Init_2 */
}

void HAL_TIM_PeriodElapsedCallback(TIM_HandleTypeDef *htim)
{
  if (htim->Instance == TIM7)
  {
    HAL_IncTick();
  }
  /* USER CODE BEGIN Callback 1 */
  vehicle_app_timer(htim);

  /* USER CODE END Callback 1 */
}

void Error_Handler(void)
{
  /* USER CODE BEGIN Error_Handler_Debug */
  vehicle_emergency_stop();
  /* User can add his own implementation to report the HAL error return state */
  __disable_irq();
  while (1)
  {
  }
  /* USER CODE END Error_Handler_Debug */
}

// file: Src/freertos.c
/* USER CODE BEGIN Header */
/**
  ******************************************************************************
  * File Name          : freertos.c
  * Description        : Code for freertos applications
  ******************************************************************************
  * @attention
  *
  * Copyright (c) 2026 STMicroelectronics.
  * All rights reserved.
  *
  * This software is licensed under terms that can be found in the LICENSE file
  * in the root directory of this software component.
  * If no LICENSE file comes with this software, it is provided AS-IS.
  *
  ******************************************************************************
  */
/* USER CODE END Header */

#include "FreeRTOS.h"
#include "task.h"
#include "main.h"

/* GetIdleTaskMemory prototype (linked to static allocation support) */
void vApplicationGetIdleTaskMemory( StaticTask_t **ppxIdleTaskTCBBuffer, StackType_t **ppxIdleTaskStackBuffer, uint32_t *pulIdleTaskStackSize );

/* Hook prototypes */
void vApplicationStackOverflowHook(xTaskHandle xTask, signed char *pcTaskName);
void vApplicationMallocFailedHook(void);

/* USER CODE BEGIN 4 */
__weak void vApplicationStackOverflowHook(xTaskHandle xTask, signed char *pcTaskName)
{
  (void)xTask; (void)pcTaskName;
   /* Run time stack overflow checking is performed if
   configCHECK_FOR_STACK_OVERFLOW is defined to 1 or 2. This hook function is
   called if a stack overflow is detected. */
}
/* USER CODE END 4 */

/* USER CODE BEGIN 5 */
__weak void vApplicationMallocFailedHook(void)
{
   /* vApplicationMallocFailedHook() will only be called if
   configUSE_MALLOC_FAILED_HOOK is set to 1 in FreeRTOSConfig.h. It is a hook
   function that will get called if a call to pvPortMalloc() fails.
   pvPortMalloc() is called internally by the kernel whenever a task, queue,
   timer or semaphore is created. It is also called by various parts of the
   demo application. If heap_1.c or heap_2.c are used, then the size of the
   heap available to pvPortMalloc() is defined by configTOTAL_HEAP_SIZE in
   FreeRTOSConfig.h, and the xPortGetFreeHeapSize() API function can be used
   to query the size of free heap space that remains (although it does not
   provide information on how the remaining heap might be fragmented). */
}
/* USER CODE END 5 */

/* USER CODE BEGIN GET_IDLE_TASK_MEMORY */
static StaticTask_t xIdleTaskTCBBuffer;
static StackType_t xIdleStack[configMINIMAL_STACK_SIZE];

void vApplicationGetIdleTaskMemory( StaticTask_t **ppxIdleTaskTCBBuffer, StackType_t **ppxIdleTaskStackBuffer, uint32_t *pulIdleTaskStackSize )
{
  *ppxIdleTaskTCBBuffer = &xIdleTaskTCBBuffer;
  *ppxIdleTaskStackBuffer = &xIdleStack[0];
  *pulIdleTaskStackSize = configMINIMAL_STACK_SIZE;
  /* place for user code */
}
/* USER CODE END GET_IDLE_TASK_MEMORY */
